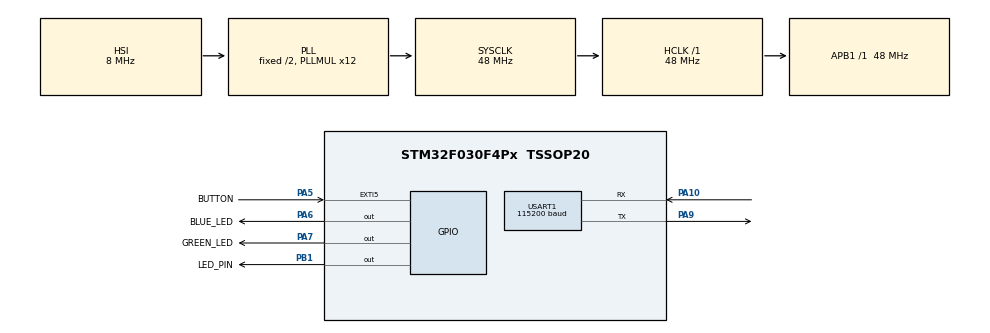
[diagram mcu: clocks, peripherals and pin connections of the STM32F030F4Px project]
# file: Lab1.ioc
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Mcu.Family=STM32F0
Mcu.Name=STM32F030F4Px
Mcu.Package=TSSOP20
NVIC.EXTI4_15_IRQn=true\:0\:0\:false\:false\:true\:true\:true
NVIC.TIM1_BRK_UP_TRG_COM_IRQn=true\:0\:0\:false\:false\:true\:true\:true
NVIC.TIM1_CC_IRQn=true\:0\:0\:false\:false\:true\:true\:true
PA10.Mode=Asynchronous
PA10.Signal=USART1_RX
PA5.GPIO_Label=BUTTON
PA5.GPIO_ModeDefaultEXTI=GPIO_MODE_IT_FALLING
PA5.GPIO_PuPd=GPIO_PULLUP
PA5.Signal=GPXTI5
PA6.GPIO_Label=BLUE_LED
PA6.Signal=GPIO_Output
PA7.GPIO_Label=GREEN_LED
PA7.Signal=GPIO_Output
PA9.Mode=Asynchronous
PA9.Signal=USART1_TX
PB1.GPIO_Label=LED_PIN
PB1.Signal=GPIO_Output
ProjectManager.HeapSize=0x200
ProjectManager.StackSize=0x400
ProjectManager.TargetToolchain=STM32CubeIDE
RCC.AHBFreq_Value=48000000
RCC.APB1Freq_Value=48000000
RCC.APB1TimFreq_Value=48000000
RCC.HCLKFreq_Value=48000000
RCC.PLLMUL=RCC_PLL_MUL12
RCC.SYSCLKFreq_VALUE=48000000
RCC.SYSCLKSource=RCC_SYSCLKSOURCE_PLLCLK
TIM1.AutoReloadPreload=TIM_AUTORELOAD_PRELOAD_ENABLE
TIM1.Channel-Output\ Compare1\ No\ Output=TIM_CHANNEL_1
TIM1.Period=100
TIM1.Prescaler=48000
USART1.BaudRate=115200
USART1.VirtualMode-Asynchronous=VM_ASYNC
VP_TIM1_VS_ClockSourceINT.Mode=Internal
VP_TIM1_VS_no_output1.Mode=Output Compare1 No Output
board=custom

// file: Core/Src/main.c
/* USER CODE BEGIN Header */
/**
  ******************************************************************************
  * @file           : main.c
  * @brief          : Main program body
  ******************************************************************************
  * @attention
  *
  * <h2><center>&copy; Copyright (c) 2019 STMicroelectronics.
  * All rights reserved.</center></h2>
  *
  * This software component is licensed by ST under BSD 3-Clause license,
  * the "License"; You may not use this file except in compliance with the
  * License. You may obtain a copy of the License at:
  *                        opensource.org/licenses/BSD-3-Clause
  *
  ******************************************************************************
  */
/* USER CODE END Header */

#include "main.h"
#include "tim.h"
#include "usart.h"
#include "gpio.h"

unsigned long int prev_time = 0;

void SystemClock_Config(void);

int main(void)
{

  /* MCU Configuration--------------------------------------------------------*/

  /* Reset of all peripherals, Initializes the Flash interface and the Systick. */
  HAL_Init();

  /* Configure the system clock */
  SystemClock_Config();

  /* Initialize all configured peripherals */
  MX_GPIO_Init();
  MX_TIM1_Init();
  MX_USART1_UART_Init();

  /* Infinite loop */
  /* USER CODE BEGIN WHILE */
  while (1)
  {

	/*	if (HAL_GPIO_ReadPin(BUTTON_GPIO_Port, BUTTON_Pin))

			HAL_GPIO_WritePin(LED_PIN_GPIO_Port, LED_PIN_Pin, 1);
		else
			HAL_GPIO_WritePin(LED_PIN_GPIO_Port, LED_PIN_Pin, 0);
*/

	  HAL_GPIO_TogglePin(LED_PIN_GPIO_Port, LED_PIN_Pin);
	  HAL_Delay(50);

    /* USER CODE END WHILE */

  }
}

void SystemClock_Config(void)
{
  RCC_OscInitTypeDef RCC_OscInitStruct = {0};
  RCC_ClkInitTypeDef RCC_ClkInitStruct = {0};
  RCC_PeriphCLKInitTypeDef PeriphClkInit = {0};

  /** Initializes the CPU, AHB and APB busses clocks
  */
  RCC_OscInitStruct.OscillatorType = RCC_OSCILLATORTYPE_HSI;
  RCC_OscInitStruct.HSIState = RCC_HSI_ON;
  RCC_OscInitStruct.HSICalibrationValue = RCC_HSICALIBRATION_DEFAULT;
  RCC_OscInitStruct.PLL.PLLState = RCC_PLL_ON;
  RCC_OscInitStruct.PLL.PLLSource = RCC_PLLSOURCE_HSI;
  RCC_OscInitStruct.PLL.PLLMUL = RCC_PLL_MUL12;
  RCC_OscInitStruct.PLL.PREDIV = RCC_PREDIV_DIV1;
  if (HAL_RCC_OscConfig(&RCC_OscInitStruct) != HAL_OK)
  {
    Error_Handler();
  }
  /** Initializes the CPU, AHB and APB busses clocks
  */
  RCC_ClkInitStruct.ClockType = RCC_CLOCKTYPE_HCLK|RCC_CLOCKTYPE_SYSCLK
                              |RCC_CLOCKTYPE_PCLK1;
  RCC_ClkInitStruct.SYSCLKSource = RCC_SYSCLKSOURCE_PLLCLK;
  RCC_ClkInitStruct.AHBCLKDivider = RCC_SYSCLK_DIV1;
  RCC_ClkInitStruct.APB1CLKDivider = RCC_HCLK_DIV1;

  if (HAL_RCC_ClockConfig(&RCC_ClkInitStruct, FLASH_LATENCY_1) != HAL_OK)
  {
    Error_Handler();
  }
  PeriphClkInit.PeriphClockSelection = RCC_PERIPHCLK_USART1;
  PeriphClkInit.Usart1ClockSelection = RCC_USART1CLKSOURCE_PCLK1;
  if (HAL_RCCEx_PeriphCLKConfig(&PeriphClkInit) != HAL_OK)
  {
    Error_Handler();
  }
}

/* USER CODE BEGIN 4 */

void HAL_GPIO_EXTI_Callback(uint16_t GPIO_Pin){
	if(GPIO_Pin  == BUTTON_Pin){
		if((HAL_GPIO_ReadPin(BUTTON_GPIO_Port, BUTTON_Pin) == 0) && (HAL_GetTick() - prev_time > 500))

			HAL_GPIO_TogglePin(BLUE_LED_GPIO_Port, BLUE_LED_Pin);

		    prev_time = HAL_GetTick();

				/*	HAL_GPIO_WritePin(BLUE_LED_GPIO_Port, BLUE_LED_Pin,1);
				else
					HAL_GPIO_WritePin(BLUE_LED_GPIO_Port, BLUE_LED_Pin,0);
*/
		//HAL_GPIO_TogglePin(BLUE_LED_GPIO_Port, BLUE_LED_Pin);
		//HAL_Delay(50);
	}
}

void  HAL_TIM_PeriodElapsedCallback(TIM_HandleTypeDef *htim){
	        HAL_GPIO_WritePin(GREEN_LED_GPIO_Port, GREEN_LED_Pin,1);
            uart_put((char *)"Led is On \r\n ");
            HAL_GPIO_WritePin(GREEN_LED_GPIO_Port, GREEN_LED_Pin,0);
            uart_put((char *)"Led is Off \r\n ");
}

/* USER CODE END 4 */

void Error_Handler(void)
{
}

/************************ (C) COPYRIGHT STMicroelectronics *****END OF FILE****/
